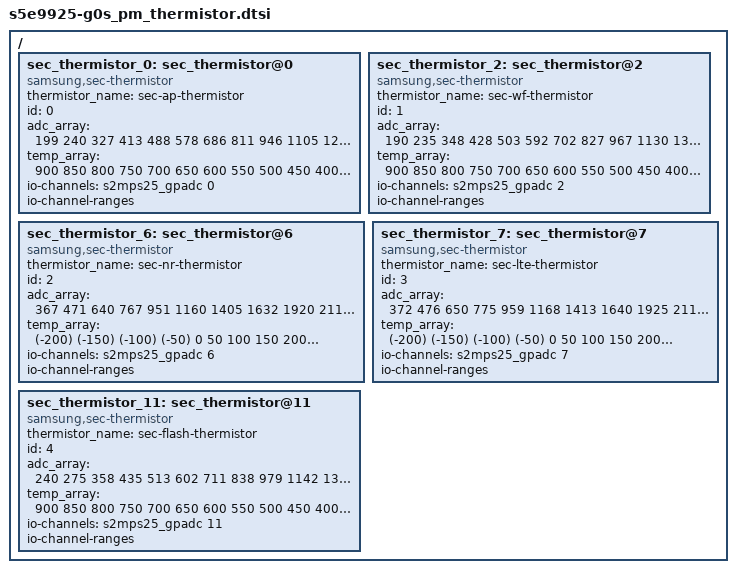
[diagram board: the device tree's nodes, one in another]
/*
 * SAMSUNG S5E9925 Power Management device tree source
 *
 * Copyright (c) 2021 Samsung Electronics Co., Ltd.
 *		http://www.samsung.com
 *
 * This program is free software; you can redistribute it and/or modify
 * it under the terms of the GNU General Public License version 2 as
 * published by the Free Software Foundation.
 */

/ {
	fragment@model {
		target-path = "/";
		__overlay__ {
			sec_thermistor_0: sec_thermistor@0 {
				compatible = "samsung,sec-thermistor";
				status = "okay";
				thermistor_name = "sec-ap-thermistor";
				id = <0>;

				adc_array = <199 240 327 413 488 578 686 811 946 1105
					1287 1462 1703 1932 2140 2401 2625 2873 3083 3261
					3450 3558 3666>;
				temp_array = <900 850 800 750 700 650 600 550 500 450
					  400 350 300 250 200 150 100 50 0 (-50)
					  (-100) (-150) (-200)>;

				io-channels = <&s2mps25_gpadc 0>;
				io-channel-names = "adc-ap-temp";
				io-channel-ranges;
			};

			sec_thermistor_2: sec_thermistor@2 {
				compatible = "samsung,sec-thermistor";
				status = "okay";
				thermistor_name = "sec-wf-thermistor";
				id = <1>;

				adc_array = <190 235 348 428 503 592 702 827 967 1130
					1312 1489 1731 1962 2200 2432 2655 2899 3107 3282
					3406 3574 3679>;
				temp_array = <900 850 800 750 700 650 600 550 500 450
					  400 350 300 250 200 150 100 50 0 (-50)
					  (-100) (-150) (-200)>;

				io-channels = <&s2mps25_gpadc 2>;
				io-channel-names = "adc-wf-temp";
				io-channel-ranges;
			};

			sec_thermistor_6: sec_thermistor@6 {
				compatible = "samsung,sec-thermistor";
				status = "okay";
				thermistor_name = "sec-nr-thermistor";
				id = <2>;

				adc_array = <367 471 640 767 951 1160 1405 1632 1920 2111
					2344 2588 2771 2953 3116 3258 3383 3493 3582 3658
					3741 3810 3870>;
				temp_array = <(-200) (-150) (-100) (-50) 0 50 100 150 200 250
					300 350 400 450 500 550 600 650 700 750
					800 850 900>;

				io-channels = <&s2mps25_gpadc 6>;
				io-channel-names = "adc-nr-temp";
				io-channel-ranges;
			};

			sec_thermistor_7: sec_thermistor@7 {
				compatible = "samsung,sec-thermistor";
				status = "okay";
				thermistor_name = "sec-lte-thermistor";
				id = <3>;

				adc_array = <372 476 650 775 959 1168 1413 1640 1925 2119
					2351 2597 2776 2958 3121 3262 3386 3495 3582 3660
					3741 3820 3850>;
				temp_array = <(-200) (-150) (-100) (-50) 0 50 100 150 200 250
					300 350 400 450 500 550 600 650 700 750
					800 850 900>;

				io-channels = <&s2mps25_gpadc 7>;
				io-channel-names = "adc-lte-temp";
				io-channel-ranges;
			};

			sec_thermistor_11: sec_thermistor@11 {
				compatible = "samsung,sec-thermistor";
				status = "okay";
				thermistor_name = "sec-flash-thermistor";
				id = <4>;

				adc_array = <240 275 358 435 513 602 711 838 979 1142
					1324 1509 1745 1976 2174 2448 2673 2912 3119 3293
					3432 3584 3688>;
				temp_array = <900 850 800 750 700 650 600 550 500 450
					  400 350 300 250 200 150 100 50 0 (-50)
					  (-100) (-150) (-200)>;

				io-channels = <&s2mps25_gpadc 11>;
				io-channel-names = "adc-flash-temp";
				io-channel-ranges;
			};
		}; /* end of __overlay__ */
	}; /* end of fragment */
}; /* end of root */
